# SAMA7G54D1G device description
Architecture: CORTEX-A7; Family: SAMA; Series: SAMA7G
Registers are 32-bit, read-write, reset 0x0 unless marked. A register's access mark holds for its fields unless they carry their own. Offsets are from the block's base; [hi:lo] are bit positions; {n}, {i} and the like mark numbered series; 'fields as' and 'values as' point back to an identical list; <NAME> marks a mode.

## ADC — Analog-to-Digital Converter
Instances: ADC 0xE1000000
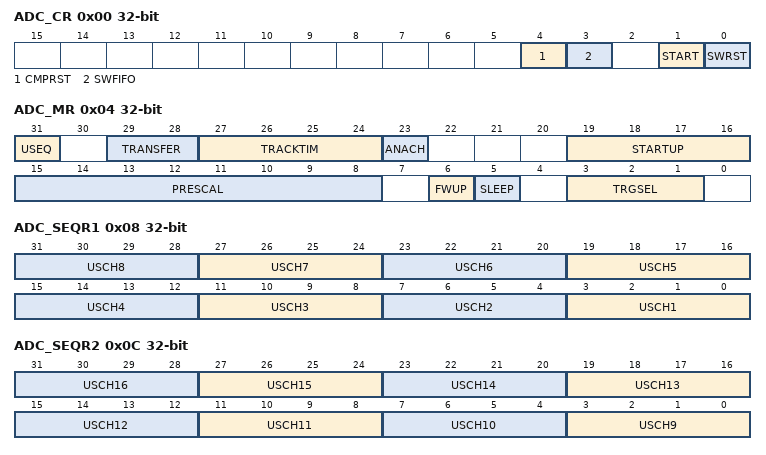
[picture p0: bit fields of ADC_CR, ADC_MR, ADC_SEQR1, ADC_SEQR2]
0x00 ADC_CR wo reset not defined — Control Register
  [4] CMPRST — Comparison Restart
    0=No effect; 1=Stops the conversion result storage until the next comparison match
  [3] SWFIFO — Software FIFO Reset
    0=No effect; 1=Resets the internal FIFO, simulating a hardware reset
  [1] START — Start Conversion
    0=No effect; 1=Begins analog-to-digital conversion
  [0] SWRST — Software Reset
    0=No effect; 1=Resets the ADC, simulating a hardware reset
0x04 ADC_MR — Mode Register
  [31] USEQ — User Sequence Enable
    0=NUM_ORDER (Normal mode: The controller converts channels in a simple numeric order depending only on the channel index.); 1=REG_ORDER (User Sequence mode: The sequence respects what is defined in ADC_SEQR1 and ADC_SEQR2 and can be used to convert the same channel several times.)
  [29:28] TRANSFER — Transfer Time
  [27:24] TRACKTIM — Tracking Time
  [23] ANACH — Analog Change
    0=NONE (No analog change on channel switching: DIFF0 is used for all channels.); 1=ALLOWED (Allows different analog settings for each channel. See ADC Channel Configuration Register.)
  [19:16] STARTUP — Startup Time
    0=SUT0 (0 period of ADCCLK); 1=SUT8 (8 periods of ADCCLK); 2=SUT16 (16 periods of ADCCLK); 3=SUT24 (24 periods of ADCCLK); 4=SUT64 (64 periods of ADCCLK); 5=SUT80 (80 periods of ADCCLK); 6=SUT96 (96 periods of ADCCLK); 7=SUT112 (112 periods of ADCCLK); 8=SUT512 (512 periods of ADCCLK); 9=SUT576 (576 periods of ADCCLK); 10=SUT640 (640 periods of ADCCLK); 11=SUT704 (704 periods of ADCCLK); 12=SUT768 (768 periods of ADCCLK); 13=SUT832 (832 periods of ADCCLK); 14=SUT896 (896 periods of ADCCLK); 15=SUT960 (960 periods of ADCCLK)
  [15:8] PRESCAL — Prescaler Rate Selection
  [6] FWUP — Fast Wakeup
    0=OFF (If SLEEP is 1, then both ADC core and reference voltage circuitry are off between conversions.); 1=ON (If SLEEP is 1, then Fast Wakeup Sleep mode: The voltage reference is on between conversions and ADC core is off.)
  [5] SLEEP — Sleep Mode
    0=NORMAL (Normal mode: The ADC core and reference voltage circuitry are kept on between conversions.); 1=SLEEP (Sleep mode: The wakeup time can be modified by programming the FWUP bit.)
  [3:1] TRGSEL — Trigger Selection
    0=ADC_TRIG0 (ADTRG); 1=ADC_TRIG1 (TIOA0 TC0); 2=ADC_TRIG2 (TIOA1 TC0); 3=ADC_TRIG3 (TIOA2 TC0); 4=ADC_TRIG4 (PWM event line 0); 5=ADC_TRIG5 (PWM event line 1); 6=ADC_TRIG6 (TIOA3/ACC); 7=ADC_TRIG7 (RTCOUT0)
0x08 ADC_SEQR1 — Channel Sequence Register 1
  [4n-1:4n-4] USCH{n} (n=1..8) — User Sequence Number {n}
0x0C ADC_SEQR2 — Channel Sequence Register 2
  [4n-33:4n-36] USCH{n} (n=9..16) — User Sequence Number {n}
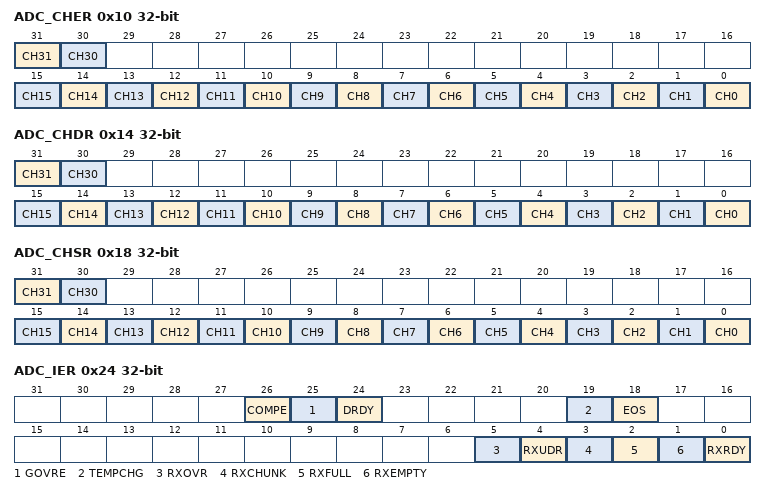
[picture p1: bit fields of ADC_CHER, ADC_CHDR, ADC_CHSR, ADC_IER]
0x10 ADC_CHER wo reset not defined (atomic set of ADC_CHSR) — Channel Enable Register
  [all] fields
    0=No effect; 1=Enables the corresponding channel
  [31] CH31 — Channel 31 Enable
  [30] CH30 — Channel 30 Enable
  [n] CH{n} (n=0..15) — Channel {n} Enable
0x14 ADC_CHDR wo reset not defined (atomic clear of ADC_CHSR) — Channel Disable Register
  [all] fields
    0=No effect; 1=Disables the corresponding channel
  [31] CH31 — Channel 31 Disable
  [30] CH30 — Channel 30 Disable
  [n] CH{n} (n=0..15) — Channel {n} Disable
0x18 ADC_CHSR ro — Channel Status Register
  [all] fields
    0=The corresponding channel (or part of sequence, see ADC_SEQyR.USCHx) is disabled; 1=The corresponding channel (or part of sequence, see ADC_SEQyR.USCHx) is enabled
  [31] CH31 — Channel 31 Status
  [30] CH30 — Channel 30 Status
  [n] CH{n} (n=0..15) — Channel {n} Status
0x20 ADC_LCDR ro — Last Converted Data Register
  [28:24] CHNBOSR <DEFAULT> — Channel Number in Oversampling Mode
  [15:0] LDATA <DEFAULT> — Last Data Converted
  [15:12] NO_OSR_CHNB <NO_OSR> — Channel Number when No Oversampling
  [11:0] NO_OSR_LDATA <NO_OSR> — Last Data Converted when No Oversampling
0x24 ADC_IER wo reset not defined (atomic set of ADC_IMR) — Interrupt Enable Register
  [26] COMPE — Comparison Event Interrupt Enable
  [25] GOVRE — General Overrun Error Interrupt Enable
  [24] DRDY — Data Ready Interrupt Enable
  [19] TEMPCHG — Temperature Change Interrupt Enable
  [18] EOS — End Of Sequence Interrupt Enable
  [5] RXOVR — Receive Over Flow Interrupt Enable
  [4] RXUDR — Receive Under Flow Interrupt Enable
  [3] RXCHUNK — Receive FIFO Chunk Interrupt Enable
  [2] RXFULL — Receive FIFO Full Interrupt Enable
  [1] RXEMPTY — Receive FIFO Empty Interrupt Enable
  [0] RXRDY — Receive Ready Interrupt Enable
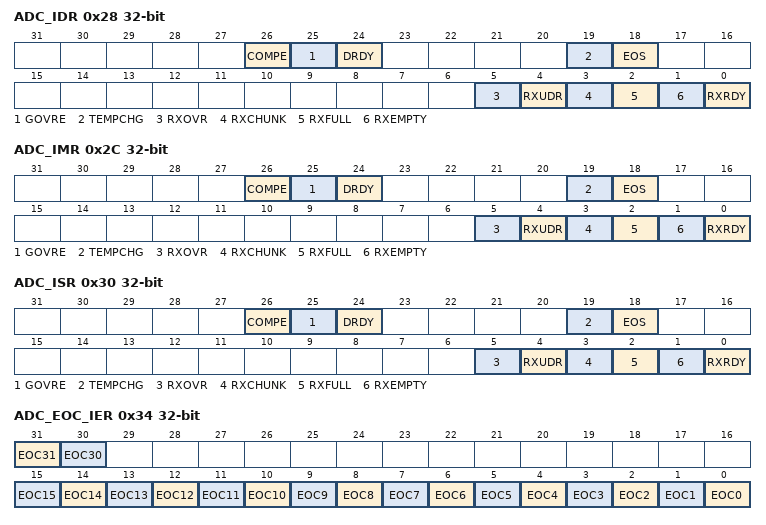
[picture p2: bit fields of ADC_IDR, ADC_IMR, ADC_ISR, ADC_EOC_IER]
0x28 ADC_IDR wo reset not defined (atomic clear of ADC_IMR) — Interrupt Disable Register
  [26] COMPE — Comparison Event Interrupt Disable
  [25] GOVRE — General Overrun Error Interrupt Disable
  [24] DRDY — Data Ready Interrupt Disable
  [19] TEMPCHG — Temperature Change Interrupt Disable
  [18] EOS — End Of Sequence Interrupt Disable
  [5] RXOVR — Receive Over Flow Interrupt Disable
  [4] RXUDR — Receive Under Flow Interrupt Disable
  [3] RXCHUNK — Receive FIFO Chunk Interrupt Disable
  [2] RXFULL — Receive FIFO Full Interrupt Disable
  [1] RXEMPTY — Receive FIFO Empty Interrupt Disable
  [0] RXRDY — Receive Ready Interrupt Disable
0x2C ADC_IMR ro — Interrupt Mask Register
  [26] COMPE — Comparison Event Interrupt Mask
  [25] GOVRE — General Overrun Error Interrupt Mask
  [24] DRDY — Data Ready Interrupt Mask
  [19] TEMPCHG — Temperature Change Interrupt Mask
  [18] EOS — End Of Sequence Interrupt Mask
  [5] RXOVR — Receive Over Flow Interrupt Mask
  [4] RXUDR — Receive Under Flow Interrupt Mask
  [3] RXCHUNK — Receive FIFO Chunk Interrupt Mask
  [2] RXFULL — Receive FIFO Full Interrupt Mask
  [1] RXEMPTY — Receive FIFO Empty Interrupt Mask
  [0] RXRDY — Receive Ready Interrupt Mask
0x30 ADC_ISR ro — Interrupt Status Register
  [26] COMPE — Comparison Event (cleared on read)
    0=No comparison event occurred since the last read of ADC_ISR; 1=At least one comparison event (defined in ADC_EMR and ADC_CWR) has occurred since the last read of ADC_ISR
  [25] GOVRE — General Overrun Error (cleared on read)
    0=No general overrun error occurred since the last read of ADC_ISR; 1=At least one general overrun error has occurred since the last read of ADC_ISR
  [24] DRDY — Data Ready (automatically set / cleared)
    0=No data has been converted since the last read of ADC_LCDR; 1=At least one data has been converted and is available in ADC_LCDR
  [19] TEMPCHG — Temperature Change (cleared on read)
    0=There is no comparison match (defined in the Temperature Compare Window register (ADC_TEMPCWR) since the last read of ADC_ISR; 1=The temperature value reported on ADC_CDRmax (max=highest index) has changed since the last read of ADC_ISR, according to what is defined in ADC_TEMPTMR and ADC_TEMPCWR
  [18] EOS — End Of Sequence (cleared on read)
    0=No sequence is in progress or the sequence is not finished. This flag is cleared when reading ADC_ISR.; 1=The sequence is complete
  [5] RXOVR — Receive Over Flow (cleared on read)
    values as GOVRE
  [4] RXUDR — Receive Under Flow (cleared on read)
    0=No general underrun error occurred since the last read of ADC_ISR; 1=At least one general underrun error has occurred since the last read of ADC_ISR
  [3] RXCHUNK — Receive FIFO Chunk (cleared on read)
    0=The number of written elements in the FIFO has been lower than or not equal to chunk_size since the last read of ADC_ISR; 1=The number of written elements in the FIFO has been greater than or equal to chunk_size since the last read of ADC_ISR
  [2] RXFULL — Receive FIFO Full (cleared on read)
    0=FIFO has not been full since the last read of ADC_ISR; 1=FIFO has been full since the last read of ADC_ISR
  [1] RXEMPTY — Receive FIFO Empty (cleared on read)
    0=FIFO has not been empty since the last read of ADC_ISR; 1=FIFO has been empty since the last read of ADC_ISR
  [0] RXRDY — Receive Ready (cleared on read)
    0=FIFO has been empty since the last read of ADC_ISR; 1=One element has been written since the last read of ADC_ISR
0x34 ADC_EOC_IER wo reset not defined (atomic set of ADC_EOC_IMR) — End Of Conversion Interrupt Enable Register
  [all] fields
    0=No effect; 1=Enables the corresponding interrupt
  [31] EOC31 — End of Conversion Interrupt Enable 31
  [30] EOC30 — End of Conversion Interrupt Enable 30
  [n] EOC{n} (n=0..15) — End of Conversion Interrupt Enable {n}
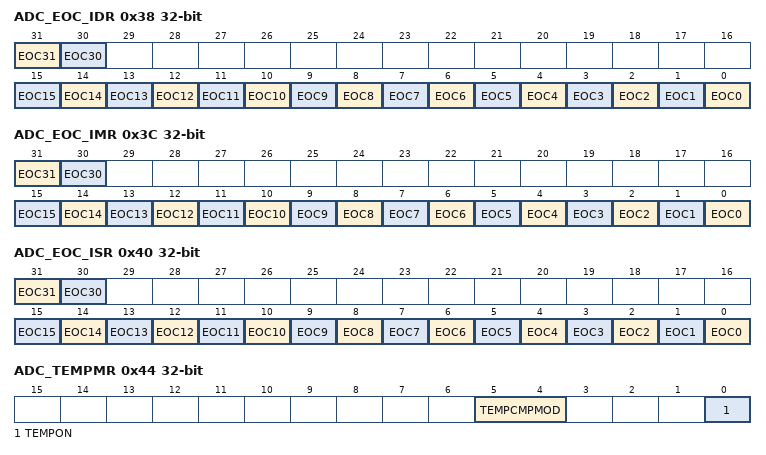
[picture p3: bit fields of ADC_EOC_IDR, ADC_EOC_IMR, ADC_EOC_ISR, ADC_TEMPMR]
0x38 ADC_EOC_IDR wo reset not defined (atomic clear of ADC_EOC_IMR) — End Of Conversion Interrupt Disable Register
  [all] fields
    0=No effect; 1=Disables the corresponding interrupt
  [31] EOC31 — End of Conversion Interrupt Disable 31
  [30] EOC30 — End of Conversion Interrupt Disable 30
  [n] EOC{n} (n=0..15) — End of Conversion Interrupt Disable {n}
0x3C ADC_EOC_IMR ro — End Of Conversion Interrupt Mask Register
  [all] fields
    0=The corresponding interrupt is disabled; 1=The corresponding interrupt is enabled
  [31] EOC31 — End of Conversion Interrupt Mask 31
  [30] EOC30 — End of Conversion Interrupt Mask 30
  [n] EOC{n} (n=0..15) — End of Conversion Interrupt Mask {n}
0x40 ADC_EOC_ISR ro — End Of Conversion Interrupt Status Register
  [all] fields
    0=The corresponding analog channel is disabled, or the conversion is not finished. This flag is cleared when reading the corresponding ADC_CDRx registers.; 1=The corresponding analog channel is enabled and conversion is complete
  [31] EOC31 — End of Conversion 31 (automatically set / cleared)
  [30] EOC30 — End of Conversion 30 (automatically set / cleared)
  [n] EOC{n} (n=0..15) — End of Conversion {n} (automatically set / cleared)
0x44 ADC_TEMPMR — Temperature Sensor Mode Register
  [5:4] TEMPCMPMOD — Temperature Comparison Mode
    0=LOW (Generates the TEMPCHG flag in ADC_ISR when the converted data is lower than the low threshold of the window.); 1=HIGH (Generates the TEMPCHG flag in ADC_ISR when the converted data is higher than the high threshold of the window.); 2=IN (Generates the TEMPCHG flag in ADC_ISR when the converted data is in the comparison window.); 3=OUT (Generates the TEMPCHG flag in ADC_ISR when the converted data is out of the comparison window.)
  [0] TEMPON — Temperature Sensor On
    0=The temperature sensor is not enabled; 1=The temperature sensor is enabled and the measurements are triggered
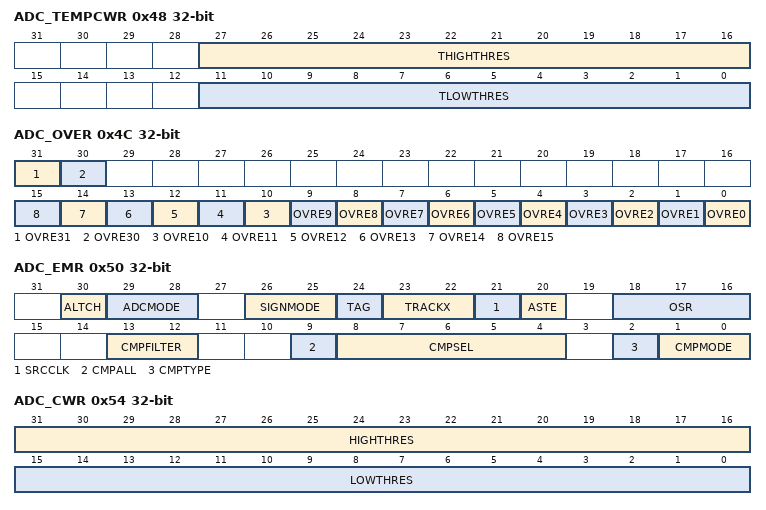
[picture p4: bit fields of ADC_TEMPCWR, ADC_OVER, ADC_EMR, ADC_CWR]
0x48 ADC_TEMPCWR — Temperature Compare Window Register
  [27:16] THIGHTHRES — Temperature High Threshold
  [11:0] TLOWTHRES — Temperature Low Threshold
0x4C ADC_OVER ro — Overrun Status Register
  [all] fields
    0=No overrun error has occurred on the corresponding channel since the last read of ADC_OVER; 1=An overrun error has occurred on the corresponding channel since the last read of ADC_OVER
  [31] OVRE31 — Overrun Error 31
  [30] OVRE30 — Overrun Error 30
  [n] OVRE{n} (n=0..15) — Overrun Error {n}
0x50 ADC_EMR — Extended Mode Register
  [30] ALTCH — Alternate Channel Selection (Safety)
    0=The regular channels are selected; 1=The alternate channels are selected
  [29:28] ADCMODE — ADC Running Mode
    0=NORMAL (Normal mode of operation.); 1=OFFSET_ERROR (Offset Error mode to measure the offset error. See Table 6-6 "ADC Running Modes".); 2=GAIN_ERROR_HIGH (Gain Error mode to measure the gain error. See Table 6-6 "ADC Running Modes".); 3=GAIN_ERROR_LOW (Gain Error mode to measure the gain error. See Table 6-6 "ADC Running Modes".)
  [26:25] SIGNMODE
    0=SE_UNSG_DF_SIGN (Single-ended channels: unsigned conversions Differential channels: signed conversions); 1=SE_SIGN_DF_UNSG (Single-ended channels: signed conversions Differential channels: unsigned conversions); 2=ALL_UNSIGNED (All channels: unsigned conversions); 3=ALL_SIGNED (All channels: signed conversions)
  [24] TAG — ADC_LCDR Tag
    0=Sets ADC_LCDR.NO_OSR_CHNB/CHNBOSR to zero; 1=Appends the channel number to the conversion result in ADC_LCDR
  [23:22] TRACKX — Tracking Time x4, x8 or x16
    0=TRACKTIMX1 (ADC_MR.TRACKTIM effect is multiplied by 1.); 1=TRACKTIMX4 (ADC_MR.TRACKTIM effect is multiplied by 4.); 2=TRACKTIMX8 (ADC_MR.TRACKTIM effect is multiplied by 8); 3=TRACKTIMX16 (ADC_MR.TRACKTIM effect is multiplied by 16.)
  [21] SRCCLK — External Clock Selection
    0=PERIPH_CLK (The peripheral clock is the source for the ADC prescaler.); 1=GCLK (GCLK is the source clock for the ADC prescaler, thus the ADC clock can be independent of the core/peripheral clock.)
  [20] ASTE — Averaging on Single Trigger Event
    0=MULTI_TRIG_AVERAGE (The average requests several trigger events.); 1=SINGLE_TRIG_AVERAGE (The average requests only one trigger event.)
  [18:16] OSR — Over Sampling Rate
    0=NO_AVERAGE (No averaging. ADC sample rate is maximum.); 1=1-bit enhanced resolution by averaging. ADC sample rate divided by 4.; 2=2-bit enhanced resolution by averaging. ADC sample rate divided by 16.; 3=1-bit enhanced resolution by averaging. ADC sample rate divided by 64; 4=2-bit enhanced resolution by averaging. ADC sample rate divided by 256.
  [13:12] CMPFILTER — Compare Event Filtering
  [9] CMPALL — Compare All Channels
    0=Only the channel indicated in CMPSEL is compared; 1=All channels are compared
  [8:4] CMPSEL — Comparison Selected Channel
  [2] CMPTYPE — Comparison Type
    0=FLAG_ONLY (Any conversion is performed and comparison function drives the COMPE flag.); 1=START_CONDITION (Comparison conditions must be met to start the storage of all conversions until ADC_CR.CMPRST is set.)
  [1:0] CMPMODE — Comparison Mode
    0=LOW (When the converted data is lower than the low threshold of the window, generates the COMPE flag in ADC_ISR or, in Partial Wakeup mode, defines the conditions to exit the system from Wait mode.); 1=HIGH (When the converted data is higher than the high threshold of the window, generates the COMPE flag in ADC_ISR or, in Partial Wakeup mode, defines the conditions to exit the system from Wait mode.); 2=IN (When the converted data is in the comparison window, generates the COMPE flag in ADC_ISR or, in Partial Wakeup mode, defines the conditions to exit the system from Wait mode.); 3=OUT (When the converted data is out of the comparison window, generates the COMPE flag in ADC_ISR or, in Partial Wakeup mode, defines the conditions to exit the system from Wait mode.)
0x54 ADC_CWR — Compare Window Register
  [31:16] HIGHTHRES — High Threshold
  [15:0] LOWTHRES — Low Threshold
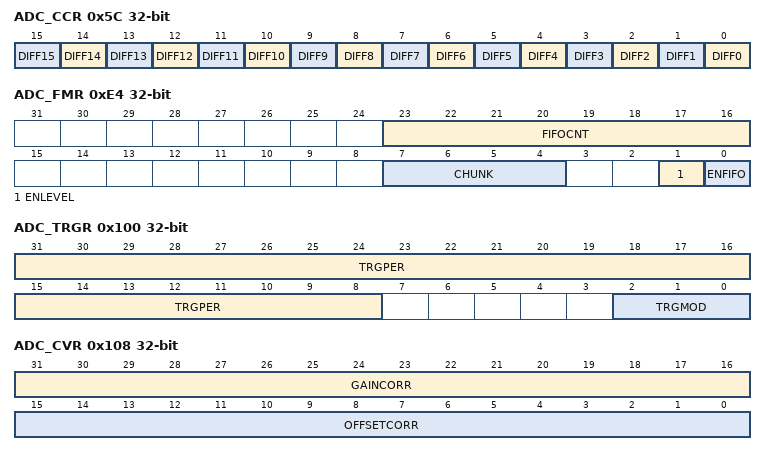
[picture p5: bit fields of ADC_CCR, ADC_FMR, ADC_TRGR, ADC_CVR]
0x5C ADC_CCR — Channel Configuration Register
  [all] fields
    0=Corresponding channel is set in Single-ended mode; 1=Corresponding channel is set in Differential mode
  [n] DIFF{n} (n=0..15) — Differential Inputs for Channel {n}
{0x60+4i} ADC_CDR[{i}] (i=0..31) ro — Channel Data Register x
  [15:0] DATA — Converted Data
0xE0 ADC_ACR reset 0x101 — Analog Control Register
  [16] SRCLCH — Source Last Channel.
    0=VTEMP (The highest index channel is driven by the output of the temperature sensor.); 1=VBG (The highest index channel is driven by the reference voltage of the temperature sensor.)
0xE4 ADC_FMR — FIFO Mode Register
  [23:16] FIFOCNT — FIFO Count (read-only)
  [7:4] CHUNK — Chunk Size
  [1] ENLEVEL — Enable Level
    0=Request to DMA is generated as soon as one data is written in FIFO when FIFO is enabled. CHUNK is not used.; 1=Request to DMA is generated as soon as the number of written elements in the FIFO is greater than or equal to CHUNK
  [0] ENFIFO — Enable FIFO
    0=FIFO is disabled; 1=FIFO is enabled
0x100 ADC_TRGR — Trigger Register
  [31:8] TRGPER — Trigger Period
  [2:0] TRGMOD — Trigger Mode
    0=NO_TRIGGER (No hardware trigger, only software trigger can start conversions); 1=EXT_TRIG_RISE (Rising edge of the selected trigger event, defined in ADC_MR.TRGSEL); 2=EXT_TRIG_FALL (Falling edge of the selected trigger event); 3=EXT_TRIG_ANY (Any edge of the selected trigger event); 5=PERIOD_TRIG (ADC internal periodic trigger (see TRGPER)); 6=CONTINUOUS (Continuous mode, free run mode)
0x104 ADC_COSR — Correction Select Register
  [4:0] CSEL — Channel Correction Select
0x108 ADC_CVR — Correction Values Register
  [31:16] GAINCORR — Gain Correction
  [15:0] OFFSETCORR — Offset Correction
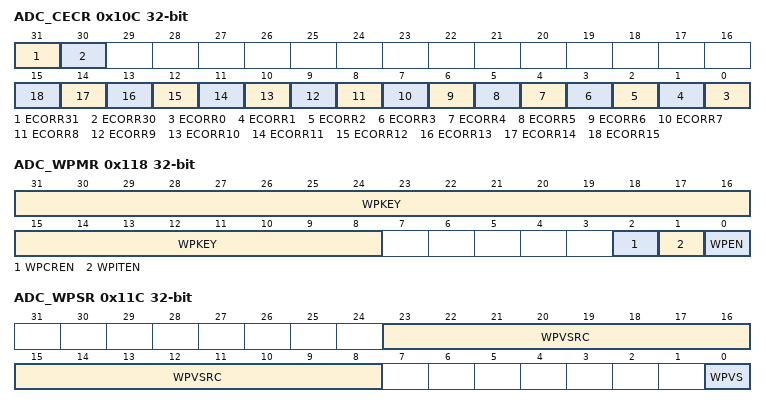
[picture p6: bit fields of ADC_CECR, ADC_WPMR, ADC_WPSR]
0x10C ADC_CECR — Channel Error Correction Register
  [all] fields
    0=Automatic error correction is disabled for channel x; 1=Automatic error correction is enabled for channel x
  [31] ECORR31 — Error Correction Enable for Channel 31
  [30] ECORR30 — Error Correction Enable for Channel 30
  [n] ECORR{n} (n=0..15) — Error Correction Enable for Channel {n}
0x118 ADC_WPMR — Write Protection Mode Register
  [31:8] WPKEY — Write Protection Key
    0x414443=PASSWD (Writing any other value in this field aborts the write operation of the WPEN bit. Always reads as 0.)
  [2] WPCREN — Write Protection Control Register Enable
    0=Disables the write protection on control registers if WPKEY corresponds to 0x414443 ("ADC" in ASCII); 1=Enables the write protection on control registers if WPKEY corresponds to 0x414443 ("ADC" in ASCII)
  [1] WPITEN — Write Protection Interrupt Enable
    0=Disables the write protection on interrupt registers if WPKEY corresponds to 0x414443 ("ADC" in ASCII); 1=Enables the write protection on interrupt registers if WPKEY corresponds to 0x414443 ("ADC" in ASCII)
  [0] WPEN — Write Protection Enable
    0=Disables write protection if WPKEY corresponds to 0x414443 ("ADC" in ASCII); 1=Enables write protection if WPKEY corresponds to 0x414443 ("ADC" in ASCII)
0x11C ADC_WPSR ro — Write Protection Status Register
  [23:8] WPVSRC — Write Protection Violation Source
  [0] WPVS — Write Protection Violation Status
    0=No write protection violation has occurred since the last read of ADC_WPSR; 1=A write protection violation has occurred since the last read of ADC_WPSR. If this violation is an unauthorized attempt to write a protected register, the associated violation is reported into WPVSRC.

## Notices in the file
Copyright (c) 2020 Microchip Technology Inc.
SPDX-License-Identifier: Apache-2.0
Licensed under the Apache License, Version 2.0 (the "License");
you may not use this file except in compliance with the License.
You may obtain a copy of the License at
http://www.apache.org/licenses/LICENSE-2.0
Unless required by applicable law or agreed to in writing, software
distributed under the License is distributed on an "AS IS" BASIS,
WITHOUT WARRANTIES OR CONDITIONS OF ANY KIND, either express or implied.
See the License for the specific language governing permissions and
limitations under the License.
